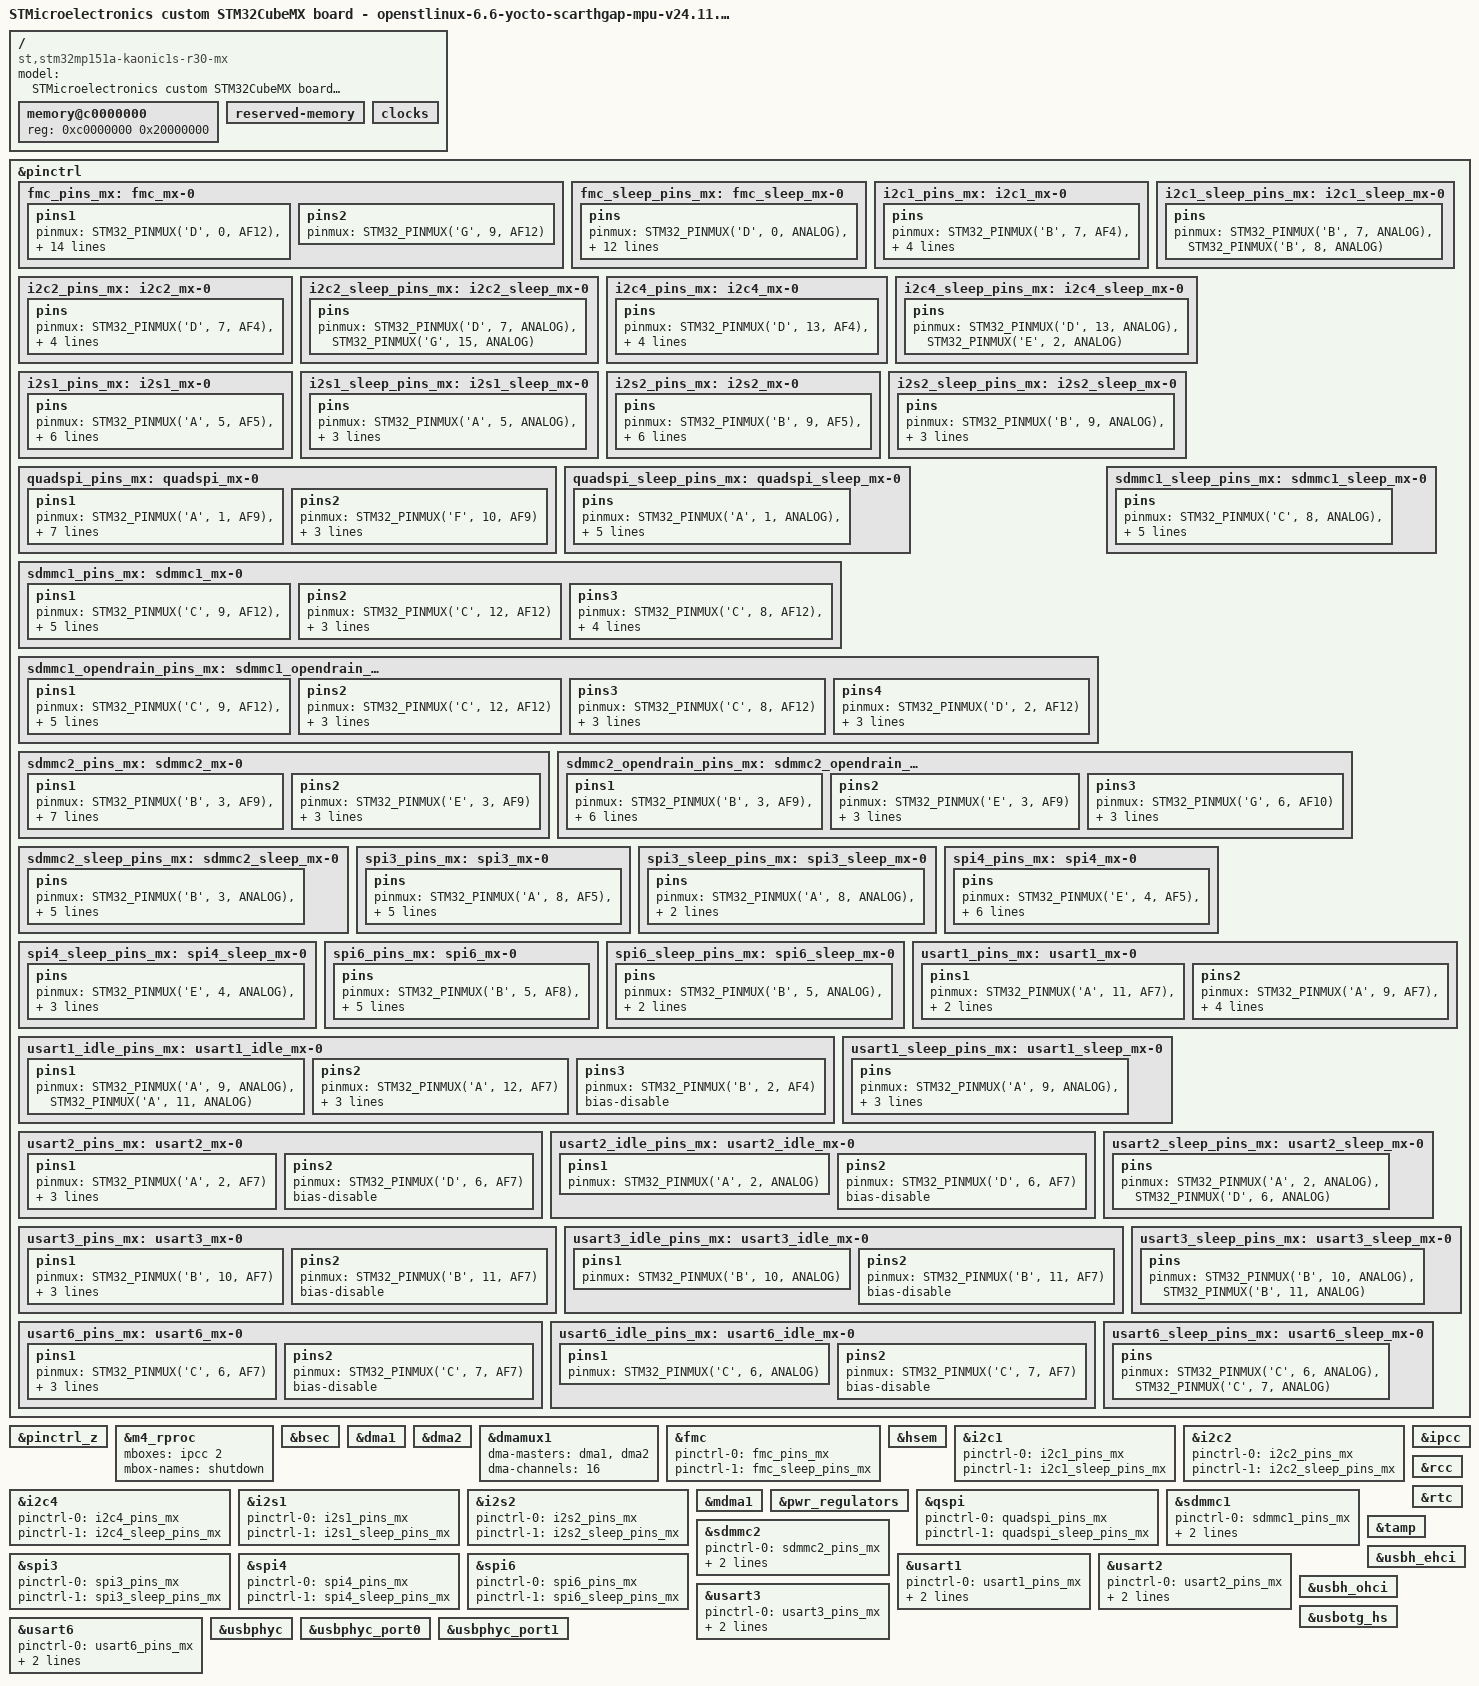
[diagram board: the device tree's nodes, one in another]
// SPDX-License-Identifier: (GPL-2.0-or-later OR BSD-3-Clause)
/*
 * Copyright (C) 2026, STMicroelectronics - All Rights Reserved
 * Author: STM32CubeMX code generation for STMicroelectronics.
 */

/* For more information on Device Tree configuration, please refer to
 * https://wiki.st.com/stm32mpu/wiki/Category:Device_tree_configuration
 */

/dts-v1/;

#include <dt-bindings/pinctrl/stm32-pinfunc.h>
#include "stm32mp151.dtsi"
#include "stm32mp15xa.dtsi"
#include "stm32mp15xxab-pinctrl.dtsi"
#include "stm32mp15-m4-srm.dtsi"

/* USER CODE BEGIN includes */
/* USER CODE END includes */

/ {
	model = "STMicroelectronics custom STM32CubeMX board - openstlinux-6.6-yocto-scarthgap-mpu-v24.11.06";
	compatible = "st,stm32mp151a-kaonic1s-r30-mx", "st,stm32mp151";

	memory@c0000000 {
		device_type = "memory";
		reg = <0xc0000000 0x20000000>;

		/* USER CODE BEGIN memory */
		/* USER CODE END memory */
	};

	reserved-memory {
		#address-cells = <1>;
		#size-cells = <1>;
		ranges;

		/* USER CODE BEGIN reserved-memory */
		/* USER CODE END reserved-memory */
	};

	/* USER CODE BEGIN root */
	/* USER CODE END root */

	clocks{

		/* USER CODE BEGIN clocks */
		/* USER CODE END clocks */
	};

}; /*root*/

&pinctrl {

	fmc_pins_mx: fmc_mx-0 {
		pins1 {
			pinmux = <STM32_PINMUX('D', 0, AF12)>, /* FMC_DA2 */
					 <STM32_PINMUX('D', 1, AF12)>, /* FMC_DA3 */
					 <STM32_PINMUX('D', 4, AF12)>, /* FMC_NOE */
					 <STM32_PINMUX('D', 5, AF12)>, /* FMC_NWE */
					 <STM32_PINMUX('D', 11, AF12)>, /* FMC_CLE */
					 <STM32_PINMUX('D', 12, AF12)>, /* FMC_ALE */
					 <STM32_PINMUX('D', 14, AF12)>, /* FMC_DA0 */
					 <STM32_PINMUX('D', 15, AF12)>, /* FMC_DA1 */
					 <STM32_PINMUX('E', 7, AF12)>, /* FMC_DA4 */
					 <STM32_PINMUX('E', 8, AF12)>, /* FMC_DA5 */
					 <STM32_PINMUX('E', 9, AF12)>, /* FMC_DA6 */
					 <STM32_PINMUX('E', 10, AF12)>; /* FMC_DA7 */
			bias-disable;
			drive-push-pull;
			slew-rate = <1>;
		};
		pins2 {
			pinmux = <STM32_PINMUX('G', 9, AF12)>; /* FMC_NE2 */
		};
	};

	fmc_sleep_pins_mx: fmc_sleep_mx-0 {
		pins {
			pinmux = <STM32_PINMUX('D', 0, ANALOG)>, /* FMC_DA2 */
					 <STM32_PINMUX('D', 1, ANALOG)>, /* FMC_DA3 */
					 <STM32_PINMUX('D', 4, ANALOG)>, /* FMC_NOE */
					 <STM32_PINMUX('D', 5, ANALOG)>, /* FMC_NWE */
					 <STM32_PINMUX('D', 11, ANALOG)>, /* FMC_CLE */
					 <STM32_PINMUX('D', 12, ANALOG)>, /* FMC_ALE */
					 <STM32_PINMUX('D', 14, ANALOG)>, /* FMC_DA0 */
					 <STM32_PINMUX('D', 15, ANALOG)>, /* FMC_DA1 */
					 <STM32_PINMUX('E', 7, ANALOG)>, /* FMC_DA4 */
					 <STM32_PINMUX('E', 8, ANALOG)>, /* FMC_DA5 */
					 <STM32_PINMUX('E', 9, ANALOG)>, /* FMC_DA6 */
					 <STM32_PINMUX('E', 10, ANALOG)>, /* FMC_DA7 */
					 <STM32_PINMUX('G', 9, ANALOG)>; /* FMC_NE2 */
		};
	};

	i2c1_pins_mx: i2c1_mx-0 {
		pins {
			pinmux = <STM32_PINMUX('B', 7, AF4)>, /* I2C1_SDA */
					 <STM32_PINMUX('B', 8, AF4)>; /* I2C1_SCL */
			bias-disable;
			drive-open-drain;
			slew-rate = <0>;
		};
	};

	i2c1_sleep_pins_mx: i2c1_sleep_mx-0 {
		pins {
			pinmux = <STM32_PINMUX('B', 7, ANALOG)>, /* I2C1_SDA */
					 <STM32_PINMUX('B', 8, ANALOG)>; /* I2C1_SCL */
		};
	};

	i2c2_pins_mx: i2c2_mx-0 {
		pins {
			pinmux = <STM32_PINMUX('D', 7, AF4)>, /* I2C2_SCL */
					 <STM32_PINMUX('G', 15, AF4)>; /* I2C2_SDA */
			bias-disable;
			drive-open-drain;
			slew-rate = <0>;
		};
	};

	i2c2_sleep_pins_mx: i2c2_sleep_mx-0 {
		pins {
			pinmux = <STM32_PINMUX('D', 7, ANALOG)>, /* I2C2_SCL */
					 <STM32_PINMUX('G', 15, ANALOG)>; /* I2C2_SDA */
		};
	};

	i2c4_pins_mx: i2c4_mx-0 {
		pins {
			pinmux = <STM32_PINMUX('D', 13, AF4)>, /* I2C4_SDA */
					 <STM32_PINMUX('E', 2, AF4)>; /* I2C4_SCL */
			bias-disable;
			drive-open-drain;
			slew-rate = <0>;
		};
	};

	i2c4_sleep_pins_mx: i2c4_sleep_mx-0 {
		pins {
			pinmux = <STM32_PINMUX('D', 13, ANALOG)>, /* I2C4_SDA */
					 <STM32_PINMUX('E', 2, ANALOG)>; /* I2C4_SCL */
		};
	};

	i2s1_pins_mx: i2s1_mx-0 {
		pins {
			pinmux = <STM32_PINMUX('A', 5, AF5)>, /* I2S1_CK */
					 <STM32_PINMUX('A', 6, AF5)>, /* I2S1_SDI */
					 <STM32_PINMUX('A', 7, AF5)>, /* I2S1_SDO */
					 <STM32_PINMUX('A', 15, AF5)>; /* I2S1_WS */
			bias-disable;
			drive-push-pull;
			slew-rate = <1>;
		};
	};

	i2s1_sleep_pins_mx: i2s1_sleep_mx-0 {
		pins {
			pinmux = <STM32_PINMUX('A', 5, ANALOG)>, /* I2S1_CK */
					 <STM32_PINMUX('A', 6, ANALOG)>, /* I2S1_SDI */
					 <STM32_PINMUX('A', 7, ANALOG)>, /* I2S1_SDO */
					 <STM32_PINMUX('A', 15, ANALOG)>; /* I2S1_WS */
		};
	};

	i2s2_pins_mx: i2s2_mx-0 {
		pins {
			pinmux = <STM32_PINMUX('B', 9, AF5)>, /* I2S2_WS */
					 <STM32_PINMUX('B', 14, AF5)>, /* I2S2_SDI */
					 <STM32_PINMUX('C', 3, AF5)>, /* I2S2_SDO */
					 <STM32_PINMUX('D', 3, AF5)>; /* I2S2_CK */
			bias-disable;
			drive-push-pull;
			slew-rate = <1>;
		};
	};

	i2s2_sleep_pins_mx: i2s2_sleep_mx-0 {
		pins {
			pinmux = <STM32_PINMUX('B', 9, ANALOG)>, /* I2S2_WS */
					 <STM32_PINMUX('B', 14, ANALOG)>, /* I2S2_SDI */
					 <STM32_PINMUX('C', 3, ANALOG)>, /* I2S2_SDO */
					 <STM32_PINMUX('D', 3, ANALOG)>; /* I2S2_CK */
		};
	};

	quadspi_pins_mx: quadspi_mx-0 {
		pins1 {
			pinmux = <STM32_PINMUX('A', 1, AF9)>, /* QUADSPI_BK1_IO3 */
					 <STM32_PINMUX('B', 6, AF10)>, /* QUADSPI_BK1_NCS */
					 <STM32_PINMUX('F', 7, AF9)>, /* QUADSPI_BK1_IO2 */
					 <STM32_PINMUX('F', 8, AF10)>, /* QUADSPI_BK1_IO0 */
					 <STM32_PINMUX('F', 9, AF10)>; /* QUADSPI_BK1_IO1 */
			bias-disable;
			drive-push-pull;
			slew-rate = <1>;
		};
		pins2 {
			pinmux = <STM32_PINMUX('F', 10, AF9)>; /* QUADSPI_CLK */
			bias-disable;
			drive-push-pull;
			slew-rate = <2>;
		};
	};

	quadspi_sleep_pins_mx: quadspi_sleep_mx-0 {
		pins {
			pinmux = <STM32_PINMUX('A', 1, ANALOG)>, /* QUADSPI_BK1_IO3 */
					 <STM32_PINMUX('B', 6, ANALOG)>, /* QUADSPI_BK1_NCS */
					 <STM32_PINMUX('F', 7, ANALOG)>, /* QUADSPI_BK1_IO2 */
					 <STM32_PINMUX('F', 8, ANALOG)>, /* QUADSPI_BK1_IO0 */
					 <STM32_PINMUX('F', 9, ANALOG)>, /* QUADSPI_BK1_IO1 */
					 <STM32_PINMUX('F', 10, ANALOG)>; /* QUADSPI_CLK */
		};
	};

	sdmmc1_pins_mx: sdmmc1_mx-0 {
		pins1 {
			pinmux = <STM32_PINMUX('C', 9, AF12)>, /* SDMMC1_D1 */
					 <STM32_PINMUX('C', 10, AF12)>, /* SDMMC1_D2 */
					 <STM32_PINMUX('C', 11, AF12)>; /* SDMMC1_D3 */
			bias-disable;
			drive-push-pull;
			slew-rate = <1>;
		};
		pins2 {
			pinmux = <STM32_PINMUX('C', 12, AF12)>; /* SDMMC1_CK */
			bias-pull-up;
			drive-push-pull;
			slew-rate = <3>;
		};
		pins3 {
			pinmux = <STM32_PINMUX('C', 8, AF12)>, /* SDMMC1_D0 */
					 <STM32_PINMUX('D', 2, AF12)>; /* SDMMC1_CMD */
			bias-pull-up;
			drive-push-pull;
			slew-rate = <1>;
		};
	};

	sdmmc1_opendrain_pins_mx: sdmmc1_opendrain_mx-0 {
		pins1 {
			pinmux = <STM32_PINMUX('C', 9, AF12)>, /* SDMMC1_D1 */
					 <STM32_PINMUX('C', 10, AF12)>, /* SDMMC1_D2 */
					 <STM32_PINMUX('C', 11, AF12)>; /* SDMMC1_D3 */
			bias-disable;
			drive-push-pull;
			slew-rate = <1>;
		};
		pins2 {
			pinmux = <STM32_PINMUX('C', 12, AF12)>; /* SDMMC1_CK */
			bias-pull-up;
			drive-push-pull;
			slew-rate = <3>;
		};
		pins3 {
			pinmux = <STM32_PINMUX('C', 8, AF12)>; /* SDMMC1_D0 */
			bias-pull-up;
			drive-push-pull;
			slew-rate = <1>;
		};
		pins4 {
			pinmux = <STM32_PINMUX('D', 2, AF12)>; /* SDMMC1_CMD */
			bias-pull-up;
			drive-open-drain;
			slew-rate = <1>;
		};
	};

	sdmmc1_sleep_pins_mx: sdmmc1_sleep_mx-0 {
		pins {
			pinmux = <STM32_PINMUX('C', 8, ANALOG)>, /* SDMMC1_D0 */
					 <STM32_PINMUX('C', 9, ANALOG)>, /* SDMMC1_D1 */
					 <STM32_PINMUX('C', 10, ANALOG)>, /* SDMMC1_D2 */
					 <STM32_PINMUX('C', 11, ANALOG)>, /* SDMMC1_D3 */
					 <STM32_PINMUX('C', 12, ANALOG)>, /* SDMMC1_CK */
					 <STM32_PINMUX('D', 2, ANALOG)>; /* SDMMC1_CMD */
		};
	};

	sdmmc2_pins_mx: sdmmc2_mx-0 {
		pins1 {
			pinmux = <STM32_PINMUX('B', 3, AF9)>, /* SDMMC2_D2 */
					 <STM32_PINMUX('B', 4, AF9)>, /* SDMMC2_D3 */
					 <STM32_PINMUX('B', 15, AF9)>, /* SDMMC2_D1 */
					 <STM32_PINMUX('E', 6, AF7)>, /* SDMMC2_D0 */
					 <STM32_PINMUX('G', 6, AF10)>; /* SDMMC2_CMD */
			bias-pull-up;
			drive-push-pull;
			slew-rate = <1>;
		};
		pins2 {
			pinmux = <STM32_PINMUX('E', 3, AF9)>; /* SDMMC2_CK */
			bias-disable;
			drive-push-pull;
			slew-rate = <3>;
		};
	};

	sdmmc2_opendrain_pins_mx: sdmmc2_opendrain_mx-0 {
		pins1 {
			pinmux = <STM32_PINMUX('B', 3, AF9)>, /* SDMMC2_D2 */
					 <STM32_PINMUX('B', 4, AF9)>, /* SDMMC2_D3 */
					 <STM32_PINMUX('B', 15, AF9)>, /* SDMMC2_D1 */
					 <STM32_PINMUX('E', 6, AF7)>; /* SDMMC2_D0 */
			bias-pull-up;
			drive-push-pull;
			slew-rate = <1>;
		};
		pins2 {
			pinmux = <STM32_PINMUX('E', 3, AF9)>; /* SDMMC2_CK */
			bias-disable;
			drive-push-pull;
			slew-rate = <3>;
		};
		pins3 {
			pinmux = <STM32_PINMUX('G', 6, AF10)>; /* SDMMC2_CMD */
			bias-pull-up;
			drive-open-drain;
			slew-rate = <1>;
		};
	};

	sdmmc2_sleep_pins_mx: sdmmc2_sleep_mx-0 {
		pins {
			pinmux = <STM32_PINMUX('B', 3, ANALOG)>, /* SDMMC2_D2 */
					 <STM32_PINMUX('B', 4, ANALOG)>, /* SDMMC2_D3 */
					 <STM32_PINMUX('B', 15, ANALOG)>, /* SDMMC2_D1 */
					 <STM32_PINMUX('E', 3, ANALOG)>, /* SDMMC2_CK */
					 <STM32_PINMUX('E', 6, ANALOG)>, /* SDMMC2_D0 */
					 <STM32_PINMUX('G', 6, ANALOG)>; /* SDMMC2_CMD */
		};
	};

	spi3_pins_mx: spi3_mx-0 {
		pins {
			pinmux = <STM32_PINMUX('A', 8, AF5)>, /* SPI3_MOSI */
					 <STM32_PINMUX('D', 10, AF5)>, /* SPI3_MISO */
					 <STM32_PINMUX('E', 0, AF5)>; /* SPI3_SCK */
			bias-disable;
			drive-push-pull;
			slew-rate = <3>;
		};
	};

	spi3_sleep_pins_mx: spi3_sleep_mx-0 {
		pins {
			pinmux = <STM32_PINMUX('A', 8, ANALOG)>, /* SPI3_MOSI */
					 <STM32_PINMUX('D', 10, ANALOG)>, /* SPI3_MISO */
					 <STM32_PINMUX('E', 0, ANALOG)>; /* SPI3_SCK */
		};
	};

	spi4_pins_mx: spi4_mx-0 {
		pins {
			pinmux = <STM32_PINMUX('E', 4, AF5)>, /* SPI4_NSS */
					 <STM32_PINMUX('E', 5, AF5)>, /* SPI4_MISO */
					 <STM32_PINMUX('E', 12, AF5)>, /* SPI4_SCK */
					 <STM32_PINMUX('E', 14, AF5)>; /* SPI4_MOSI */
			bias-disable;
			drive-push-pull;
			slew-rate = <3>;
		};
	};

	spi4_sleep_pins_mx: spi4_sleep_mx-0 {
		pins {
			pinmux = <STM32_PINMUX('E', 4, ANALOG)>, /* SPI4_NSS */
					 <STM32_PINMUX('E', 5, ANALOG)>, /* SPI4_MISO */
					 <STM32_PINMUX('E', 12, ANALOG)>, /* SPI4_SCK */
					 <STM32_PINMUX('E', 14, ANALOG)>; /* SPI4_MOSI */
		};
	};

	spi6_pins_mx: spi6_mx-0 {
		pins {
			pinmux = <STM32_PINMUX('B', 5, AF8)>, /* SPI6_MOSI */
					 <STM32_PINMUX('G', 12, AF5)>, /* SPI6_MISO */
					 <STM32_PINMUX('G', 13, AF5)>; /* SPI6_SCK */
			bias-disable;
			drive-push-pull;
			slew-rate = <3>;
		};
	};

	spi6_sleep_pins_mx: spi6_sleep_mx-0 {
		pins {
			pinmux = <STM32_PINMUX('B', 5, ANALOG)>, /* SPI6_MOSI */
					 <STM32_PINMUX('G', 12, ANALOG)>, /* SPI6_MISO */
					 <STM32_PINMUX('G', 13, ANALOG)>; /* SPI6_SCK */
		};
	};

	usart1_pins_mx: usart1_mx-0 {
		pins1 {
			pinmux = <STM32_PINMUX('A', 11, AF7)>, /* USART1_CTS */
					 <STM32_PINMUX('B', 2, AF4)>; /* USART1_RX */
			bias-disable;
		};
		pins2 {
			pinmux = <STM32_PINMUX('A', 9, AF7)>, /* USART1_TX */
					 <STM32_PINMUX('A', 12, AF7)>; /* USART1_RTS */
			bias-disable;
			drive-push-pull;
			slew-rate = <0>;
		};
	};

	usart1_idle_pins_mx: usart1_idle_mx-0 {
		pins1 {
			pinmux = <STM32_PINMUX('A', 9, ANALOG)>, /* USART1_TX */
					 <STM32_PINMUX('A', 11, ANALOG)>; /* USART1_CTS */
		};
		pins2 {
			pinmux = <STM32_PINMUX('A', 12, AF7)>; /* USART1_RTS */
			bias-disable;
			drive-push-pull;
			slew-rate = <0>;
		};
		pins3 {
			pinmux = <STM32_PINMUX('B', 2, AF4)>; /* USART1_RX */
			bias-disable;
		};
	};

	usart1_sleep_pins_mx: usart1_sleep_mx-0 {
		pins {
			pinmux = <STM32_PINMUX('A', 9, ANALOG)>, /* USART1_TX */
					 <STM32_PINMUX('A', 11, ANALOG)>, /* USART1_CTS */
					 <STM32_PINMUX('A', 12, ANALOG)>, /* USART1_RTS */
					 <STM32_PINMUX('B', 2, ANALOG)>; /* USART1_RX */
		};
	};

	usart2_pins_mx: usart2_mx-0 {
		pins1 {
			pinmux = <STM32_PINMUX('A', 2, AF7)>; /* USART2_TX */
			bias-disable;
			drive-push-pull;
			slew-rate = <0>;
		};
		pins2 {
			pinmux = <STM32_PINMUX('D', 6, AF7)>; /* USART2_RX */
			bias-disable;
		};
	};

	usart2_idle_pins_mx: usart2_idle_mx-0 {
		pins1 {
			pinmux = <STM32_PINMUX('A', 2, ANALOG)>; /* USART2_TX */
		};
		pins2 {
			pinmux = <STM32_PINMUX('D', 6, AF7)>; /* USART2_RX */
			bias-disable;
		};
	};

	usart2_sleep_pins_mx: usart2_sleep_mx-0 {
		pins {
			pinmux = <STM32_PINMUX('A', 2, ANALOG)>, /* USART2_TX */
					 <STM32_PINMUX('D', 6, ANALOG)>; /* USART2_RX */
		};
	};

	usart3_pins_mx: usart3_mx-0 {
		pins1 {
			pinmux = <STM32_PINMUX('B', 10, AF7)>; /* USART3_TX */
			bias-disable;
			drive-push-pull;
			slew-rate = <0>;
		};
		pins2 {
			pinmux = <STM32_PINMUX('B', 11, AF7)>; /* USART3_RX */
			bias-disable;
		};
	};

	usart3_idle_pins_mx: usart3_idle_mx-0 {
		pins1 {
			pinmux = <STM32_PINMUX('B', 10, ANALOG)>; /* USART3_TX */
		};
		pins2 {
			pinmux = <STM32_PINMUX('B', 11, AF7)>; /* USART3_RX */
			bias-disable;
		};
	};

	usart3_sleep_pins_mx: usart3_sleep_mx-0 {
		pins {
			pinmux = <STM32_PINMUX('B', 10, ANALOG)>, /* USART3_TX */
					 <STM32_PINMUX('B', 11, ANALOG)>; /* USART3_RX */
		};
	};

	usart6_pins_mx: usart6_mx-0 {
		pins1 {
			pinmux = <STM32_PINMUX('C', 6, AF7)>; /* USART6_TX */
			bias-disable;
			drive-push-pull;
			slew-rate = <0>;
		};
		pins2 {
			pinmux = <STM32_PINMUX('C', 7, AF7)>; /* USART6_RX */
			bias-disable;
		};
	};

	usart6_idle_pins_mx: usart6_idle_mx-0 {
		pins1 {
			pinmux = <STM32_PINMUX('C', 6, ANALOG)>; /* USART6_TX */
		};
		pins2 {
			pinmux = <STM32_PINMUX('C', 7, AF7)>; /* USART6_RX */
			bias-disable;
		};
	};

	usart6_sleep_pins_mx: usart6_sleep_mx-0 {
		pins {
			pinmux = <STM32_PINMUX('C', 6, ANALOG)>, /* USART6_TX */
					 <STM32_PINMUX('C', 7, ANALOG)>; /* USART6_RX */
		};
	};

	/* USER CODE BEGIN pinctrl */
	/* USER CODE END pinctrl */
};

&pinctrl_z {

	/* USER CODE BEGIN pinctrl_z */
	/* USER CODE END pinctrl_z */
};

&m4_rproc{
	/*Restriction: "memory-region" property is not managed - please to use User-Section if needed*/
	mboxes = <&ipcc 2>;
	mbox-names = "shutdown";
	status = "okay";

	/* USER CODE BEGIN m4_rproc */
	/* USER CODE END m4_rproc */
};

&bsec {
	status = "okay";

	/* USER CODE BEGIN bsec */
	/* USER CODE END bsec */
};

&dma1 {
	status = "okay";

	/* USER CODE BEGIN dma1 */
	/* USER CODE END dma1 */
};

&dma2 {
	status = "okay";

	/* USER CODE BEGIN dma2 */
	/* USER CODE END dma2 */
};

&dmamux1 {
	status = "okay";

	dma-masters = <&dma1 &dma2>;
	dma-channels = <16>;

	/* USER CODE BEGIN dmamux1 */
	/* USER CODE END dmamux1 */
};

&fmc {
	pinctrl-names = "default", "sleep";
	pinctrl-0 = <&fmc_pins_mx>;
	pinctrl-1 = <&fmc_sleep_pins_mx>;
	status = "okay";

	/* USER CODE BEGIN fmc */
	/* USER CODE END fmc */
};

&hsem {
	status = "okay";

	/* USER CODE BEGIN hsem */
	/* USER CODE END hsem */
};

&i2c1 {
	pinctrl-names = "default", "sleep";
	pinctrl-0 = <&i2c1_pins_mx>;
	pinctrl-1 = <&i2c1_sleep_pins_mx>;
	status = "okay";

	/* USER CODE BEGIN i2c1 */
	/* USER CODE END i2c1 */
};

&i2c2 {
	pinctrl-names = "default", "sleep";
	pinctrl-0 = <&i2c2_pins_mx>;
	pinctrl-1 = <&i2c2_sleep_pins_mx>;
	status = "okay";

	/* USER CODE BEGIN i2c2 */
	/* USER CODE END i2c2 */
};

&i2c4 {
	pinctrl-names = "default", "sleep";
	pinctrl-0 = <&i2c4_pins_mx>;
	pinctrl-1 = <&i2c4_sleep_pins_mx>;
	status = "okay";

	/* USER CODE BEGIN i2c4 */
	/* USER CODE END i2c4 */
};

&i2s1 {
	pinctrl-names = "default", "sleep";
	pinctrl-0 = <&i2s1_pins_mx>;
	pinctrl-1 = <&i2s1_sleep_pins_mx>;
	status = "okay";

	/* USER CODE BEGIN i2s1 */
	/* USER CODE END i2s1 */
};

&i2s2 {
	pinctrl-names = "default", "sleep";
	pinctrl-0 = <&i2s2_pins_mx>;
	pinctrl-1 = <&i2s2_sleep_pins_mx>;
	status = "okay";

	/* USER CODE BEGIN i2s2 */
	/* USER CODE END i2s2 */
};

&ipcc {
	status = "okay";

	/* USER CODE BEGIN ipcc */
	/* USER CODE END ipcc */
};

&mdma1 {
	status = "okay";

	/* USER CODE BEGIN mdma1 */
	/* USER CODE END mdma1 */
};

&pwr_regulators {
	status = "okay";

	/* USER CODE BEGIN pwr_regulators */
	/* USER CODE END pwr_regulators */
};

&qspi {
	pinctrl-names = "default", "sleep";
	pinctrl-0 = <&quadspi_pins_mx>;
	pinctrl-1 = <&quadspi_sleep_pins_mx>;
	status = "okay";

	/* USER CODE BEGIN qspi */
	/* USER CODE END qspi */
};

&rcc {
	status = "okay";

	/* USER CODE BEGIN rcc */
	/* USER CODE END rcc */
};

&rtc {
	status = "okay";

	/* USER CODE BEGIN rtc */
	/* USER CODE END rtc */
};

&sdmmc1 {
	pinctrl-names = "default", "opendrain", "sleep";
	pinctrl-0 = <&sdmmc1_pins_mx>;
	pinctrl-1 = <&sdmmc1_opendrain_pins_mx>;
	pinctrl-2 = <&sdmmc1_sleep_pins_mx>;
	status = "okay";

	/* USER CODE BEGIN sdmmc1 */
	/* USER CODE END sdmmc1 */
};

&sdmmc2 {
	pinctrl-names = "default", "opendrain", "sleep";
	pinctrl-0 = <&sdmmc2_pins_mx>;
	pinctrl-1 = <&sdmmc2_opendrain_pins_mx>;
	pinctrl-2 = <&sdmmc2_sleep_pins_mx>;
	status = "okay";

	/* USER CODE BEGIN sdmmc2 */
	/* USER CODE END sdmmc2 */
};

&spi3 {
	pinctrl-names = "default", "sleep";
	pinctrl-0 = <&spi3_pins_mx>;
	pinctrl-1 = <&spi3_sleep_pins_mx>;
	status = "okay";

	/* USER CODE BEGIN spi3 */
	/* USER CODE END spi3 */
};

&spi4 {
	pinctrl-names = "default", "sleep";
	pinctrl-0 = <&spi4_pins_mx>;
	pinctrl-1 = <&spi4_sleep_pins_mx>;
	status = "okay";

	/* USER CODE BEGIN spi4 */
	/* USER CODE END spi4 */
};

&spi6 {
	pinctrl-names = "default", "sleep";
	pinctrl-0 = <&spi6_pins_mx>;
	pinctrl-1 = <&spi6_sleep_pins_mx>;
	status = "okay";

	/* USER CODE BEGIN spi6 */
	/* USER CODE END spi6 */
};

&tamp {
	status = "okay";

	/* USER CODE BEGIN tamp */
	/* USER CODE END tamp */
};

&usart1 {
	pinctrl-names = "default", "idle", "sleep";
	pinctrl-0 = <&usart1_pins_mx>;
	pinctrl-1 = <&usart1_idle_pins_mx>;
	pinctrl-2 = <&usart1_sleep_pins_mx>;
	status = "okay";

	/* USER CODE BEGIN usart1 */
	/* USER CODE END usart1 */
};

&usart2 {
	pinctrl-names = "default", "idle", "sleep";
	pinctrl-0 = <&usart2_pins_mx>;
	pinctrl-1 = <&usart2_idle_pins_mx>;
	pinctrl-2 = <&usart2_sleep_pins_mx>;
	status = "okay";

	/* USER CODE BEGIN usart2 */
	/* USER CODE END usart2 */
};

&usart3 {
	pinctrl-names = "default", "idle", "sleep";
	pinctrl-0 = <&usart3_pins_mx>;
	pinctrl-1 = <&usart3_idle_pins_mx>;
	pinctrl-2 = <&usart3_sleep_pins_mx>;
	status = "okay";

	/* USER CODE BEGIN usart3 */
	/* USER CODE END usart3 */
};

&usart6 {
	pinctrl-names = "default", "idle", "sleep";
	pinctrl-0 = <&usart6_pins_mx>;
	pinctrl-1 = <&usart6_idle_pins_mx>;
	pinctrl-2 = <&usart6_sleep_pins_mx>;
	status = "okay";

	/* USER CODE BEGIN usart6 */
	/* USER CODE END usart6 */
};

&usbh_ehci {
	status = "okay";

	/* USER CODE BEGIN usbh_ehci */
	/* USER CODE END usbh_ehci */
};

&usbh_ohci {
	status = "okay";

	/* USER CODE BEGIN usbh_ohci */
	/* USER CODE END usbh_ohci */
};

&usbotg_hs {
	status = "okay";

	/* USER CODE BEGIN usbotg_hs */
	/* USER CODE END usbotg_hs */
};

&usbphyc {
	status = "okay";

	/* USER CODE BEGIN usbphyc */
	/* USER CODE END usbphyc */
};

&usbphyc_port0 {
	status = "okay";

	/* USER CODE BEGIN usbphyc_port0 */
	/* USER CODE END usbphyc_port0 */
};

&usbphyc_port1 {
	status = "okay";

	/* USER CODE BEGIN usbphyc_port1 */
	/* USER CODE END usbphyc_port1 */
};

/* USER CODE BEGIN addons */
/* USER CODE END addons */

